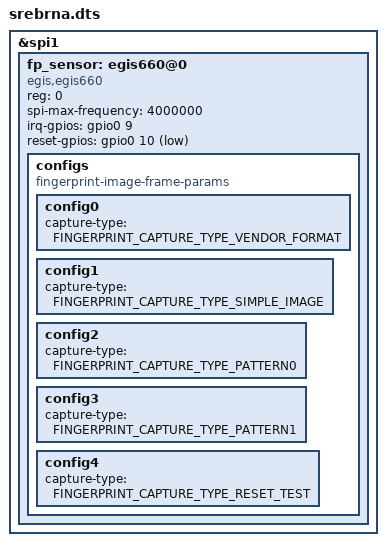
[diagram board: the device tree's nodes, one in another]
/* Copyright 2025 The ChromiumOS Authors.
 * Use of this source code is governed by a BSD-style license that can be
 * found in the LICENSE file.
 */

#include "common.dtsi"

#define EGIG660_COMMON_IMAGE_PROPS \
	width = <96>; \
	height = <100>; \
	bits-per-pixel = <8>; \
	frame-size = <10260>; \
	v4l2-pixel-format = "V4L2_PIX_FMT_GREY";

&spi1 {
	fp_sensor: egis660@0 {
		compatible = "egis,egis660";
		reg = <0>;
		spi-max-frequency = <4000000>;

		configs {
			compatible = "fingerprint-image-frame-params";
			config0 {
				EGIG660_COMMON_IMAGE_PROPS
				capture-type = "FINGERPRINT_CAPTURE_TYPE_VENDOR_FORMAT";
			};
			config1 {
				EGIG660_COMMON_IMAGE_PROPS
				capture-type = "FINGERPRINT_CAPTURE_TYPE_SIMPLE_IMAGE";
			};
			config2 {
				EGIG660_COMMON_IMAGE_PROPS
				capture-type = "FINGERPRINT_CAPTURE_TYPE_PATTERN0";
			};
			config3 {
				EGIG660_COMMON_IMAGE_PROPS
				capture-type = "FINGERPRINT_CAPTURE_TYPE_PATTERN1";
			};
			config4 {
				EGIG660_COMMON_IMAGE_PROPS
				capture-type = "FINGERPRINT_CAPTURE_TYPE_RESET_TEST";
			};
		};

		irq-gpios = <&gpio0 9 GPIO_ACTIVE_HIGH>;
		reset-gpios = <&gpio0 10 GPIO_ACTIVE_LOW>;
	};
};
